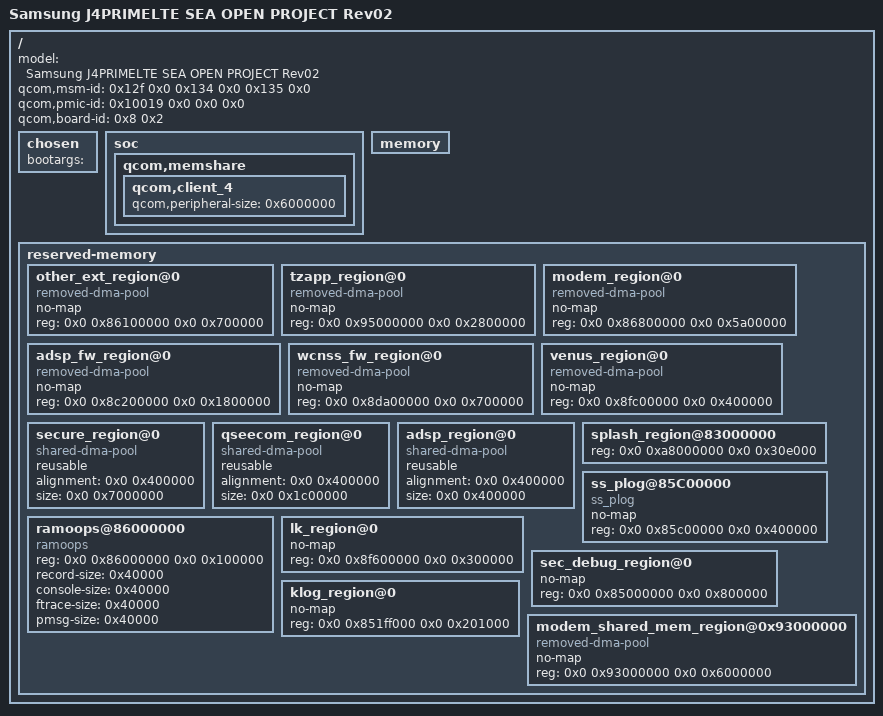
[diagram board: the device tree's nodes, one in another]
/dts-v1/;

/ {
	model = "Samsung J4PRIMELTE SEA OPEN PROJECT Rev02";
	qcom,msm-id = <0x12f 0x0 0x134 0x0 0x135 0x0>;
	qcom,pmic-id = <0x10019 0x0 0x0 0x0>;
	qcom,board-id = <0x8 0x2>;

	chosen {
		// need a dummy bootargs for bootloader to append to
		bootargs = "";
	};

	soc {
		#address-cells = <1>;
		#size-cells = <1>;
		ranges = <0x0 0x0 0x0 0xffffffff>;

		qcom,memshare {
			qcom,client_4 {
				qcom,peripheral-size = <0x6000000>;
			};
		};
	};

	memory {
		device_type = "memory";
	};

	reserved-memory {
		#address-cells = <0x2>;
		#size-cells = <0x2>;
		ranges;

		other_ext_region@0 {
			compatible = "removed-dma-pool";
			no-map;
			reg = <0x0 0x86100000 0x0 0x700000>;
		};

		tzapp_region@0 {
			compatible = "removed-dma-pool";
			no-map;
			reg = <0x0 0x95000000 0x0 0x2800000>;
		};

		modem_region@0 {
			compatible = "removed-dma-pool";
			no-map;
			reg = <0x0 0x86800000 0x0 0x5a00000>;
			linux,phandle = <0x127>;
			phandle = <0x127>;
		};

		adsp_fw_region@0 {
			compatible = "removed-dma-pool";
			no-map;
			reg = <0x0 0x8c200000 0x0 0x1800000>;
			linux,phandle = <0x12a>;
			phandle = <0x12a>;
		};

		wcnss_fw_region@0 {
			compatible = "removed-dma-pool";
			no-map;
			reg = <0x0 0x8da00000 0x0 0x700000>;
			linux,phandle = <0x12d>;
			phandle = <0x12d>;
		};

		venus_region@0 {
			compatible = "removed-dma-pool";
			no-map;
			reg = <0x0 0x8fc00000 0x0 0x400000>;
			linux,phandle = <0x12e>;
			phandle = <0x12e>;
		};

		secure_region@0 {
			compatible = "shared-dma-pool";
			reusable;
			alignment = <0x0 0x400000>;
			size = <0x0 0x7000000>;
			linux,phandle = <0x3e>;
			phandle = <0x3e>;
		};

		qseecom_region@0 {
			compatible = "shared-dma-pool";
			reusable;
			alignment = <0x0 0x400000>;
			size = <0x0 0x1c00000>;
			linux,phandle = <0x3f>;
			phandle = <0x3f>;
		};

		adsp_region@0 {
			compatible = "shared-dma-pool";
			reusable;
			alignment = <0x0 0x400000>;
			size = <0x0 0x400000>;
			linux,phandle = <0x11a>;
			phandle = <0x11a>;
		};

		splash_region@83000000 {
			reg = <0x0 0xa8000000 0x0 0x30e000>;
			linux,phandle = <0xb7>;
			phandle = <0xb7>;
		};

		ss_plog@85C00000 {
			compatible = "ss_plog";
			no-map;
			reg = <0x0 0x85c00000 0x0 0x400000>;
		};

		ramoops@86000000 {
			compatible = "ramoops";
			reg = <0x0 0x86000000 0x0 0x100000>;
			record-size = <0x40000>;
			console-size = <0x40000>;
			ftrace-size = <0x40000>;
			pmsg-size = <0x40000>;
		};

		lk_region@0 {
			no-map;
			reg = <0x0 0x8f600000 0x0 0x300000>;
		};

		sec_debug_region@0 {
			no-map;
			reg = <0x0 0x85000000 0x0 0x800000>;
		};

		klog_region@0 {
			no-map;
			reg = <0x0 0x851ff000 0x0 0x201000>;
		};

		modem_shared_mem_region@0x93000000 {
			compatible = "removed-dma-pool";
			no-map;
			reg = <0x0 0x93000000 0x0 0x6000000>;
			linux,phandle = <0x107>;
			phandle = <0x107>;
		};
	};
};
